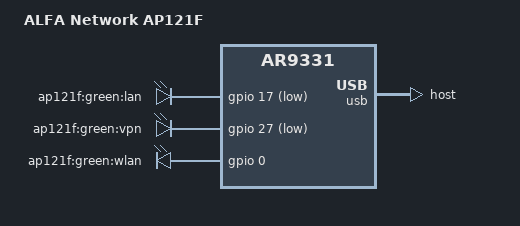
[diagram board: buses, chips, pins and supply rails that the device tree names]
// SPDX-License-Identifier: GPL-2.0-or-later OR MIT

#include "ar9331_alfa-network_ap121f.dtsi"

/ {
	model = "ALFA Network AP121F";
	compatible = "alfa-network,ap121f", "qca,ar9331";

	leds {
		compatible = "gpio-leds";

		lan {
			label = "ap121f:green:lan";
			gpios = <&gpio 17 GPIO_ACTIVE_LOW>;
		};

		led_vpn: vpn {
			label = "ap121f:green:vpn";
			gpios = <&gpio 27 GPIO_ACTIVE_LOW>;
		};

		wlan {
			label = "ap121f:green:wlan";
			gpios = <&gpio 0 GPIO_ACTIVE_HIGH>;
			linux,default-trigger = "phy0tpt";
		};
	};
};

&usb {
	dr_mode = "host";
};
